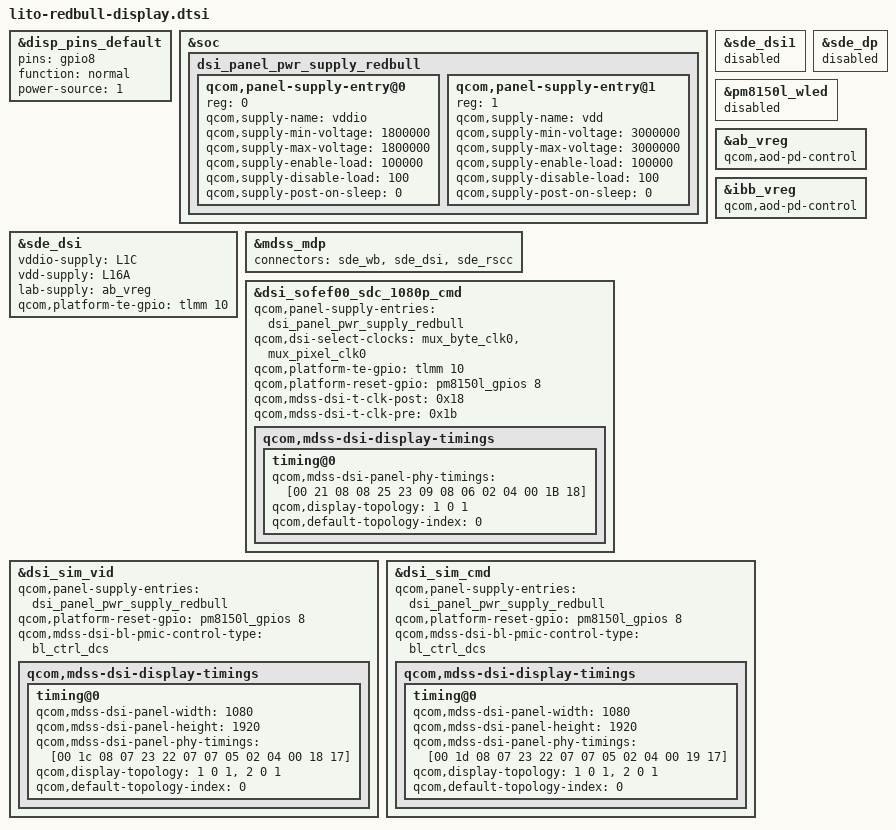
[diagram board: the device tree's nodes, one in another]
// SPDX-License-Identifier: GPL-2.0
/* Copyright (c) 2019, The Linux Foundation. All rights reserved.
 *
 * This program is free software; you can redistribute it and/or modify
 * it under the terms of the GNU General Public License version 2 and
 * only version 2 as published by the Free Software Foundation.
 *
 * This program is distributed in the hope that it will be useful,
 * but WITHOUT ANY WARRANTY; without even the implied warranty of
 * MERCHANTABILITY or FITNESS FOR A PARTICULAR PURPOSE.  See the
 * GNU General Public License for more details.
 */

#include "qcom-base/lito-sde-display.dtsi"
#include "dsi-panel-sofef00-1080p-cmd.dtsi"

&disp_pins_default {
	pins = "gpio8";
	function = "normal";
	power-source = <1>;
};

&soc {
	dsi_panel_pwr_supply_redbull: dsi_panel_pwr_supply_redbull {
		#address-cells = <1>;
		#size-cells = <0>;

		qcom,panel-supply-entry@0 {
			reg = <0>;
			qcom,supply-name = "vddio";
			qcom,supply-min-voltage = <1800000>;
			qcom,supply-max-voltage = <1800000>;
			qcom,supply-enable-load = <100000>;
			qcom,supply-disable-load = <100>;
			qcom,supply-post-on-sleep = <0>;
		};

		qcom,panel-supply-entry@1 {
			reg = <1>;
			qcom,supply-name = "vdd";
			qcom,supply-min-voltage = <3000000>;
			qcom,supply-max-voltage = <3000000>;
			qcom,supply-enable-load = <100000>;
			qcom,supply-disable-load = <100>;
			qcom,supply-post-on-sleep = <0>;
		};
	};
};

&sde_dsi {
	vddio-supply = <&L1C>;
	vdd-supply = <&L16A>;
	lab-supply = <&ab_vreg>;
	qcom,platform-te-gpio = <&tlmm 10 0>;
};

&sde_dsi1 {
	status = "disabled";
};

&sde_dp {
	status = "disabled";
};

&mdss_mdp {
	connectors = <&sde_wb &sde_dsi &sde_rscc>;
};

&pm8150l_wled {
	status = "disabled";
};

&ab_vreg {
	qcom,aod-pd-control;
};

&ibb_vreg {
	qcom,aod-pd-control;
};

&dsi_sofef00_sdc_1080p_cmd {
	qcom,panel-supply-entries = <&dsi_panel_pwr_supply_redbull>;
	qcom,dsi-select-clocks = "mux_byte_clk0", "mux_pixel_clk0";
	qcom,platform-te-gpio = <&tlmm 10 0>;
	qcom,platform-reset-gpio = <&pm8150l_gpios 8 0>;
	qcom,mdss-dsi-t-clk-post = <0x18>;
	qcom,mdss-dsi-t-clk-pre = <0x1b>;
	qcom,mdss-dsi-display-timings {
		timing@0 {
			qcom,mdss-dsi-panel-phy-timings = [00 21 08 08 25 23 09
				08 06 02 04 00 1B 18];
			qcom,display-topology = <1 0 1>;
			qcom,default-topology-index = <0>;
		};
	};
};

&dsi_sim_vid {
	qcom,panel-supply-entries = <&dsi_panel_pwr_supply_redbull>;
	qcom,platform-reset-gpio = <&pm8150l_gpios 8 0>;
	qcom,mdss-dsi-bl-pmic-control-type = "bl_ctrl_dcs";
	qcom,mdss-dsi-display-timings {
		timing@0 {
			qcom,mdss-dsi-panel-width = <1080>;
			qcom,mdss-dsi-panel-height = <1920>;
			qcom,mdss-dsi-panel-phy-timings = [00 1c 08 07 23 22 07
				07 05 02 04 00 18 17];
			qcom,display-topology = <1 0 1>,
						<2 0 1>;
			qcom,default-topology-index = <0>;
		};
	};
};

&dsi_sim_cmd {
	qcom,panel-supply-entries = <&dsi_panel_pwr_supply_redbull>;
	qcom,platform-reset-gpio = <&pm8150l_gpios 8 0>;
	qcom,mdss-dsi-bl-pmic-control-type = "bl_ctrl_dcs";
	qcom,mdss-dsi-display-timings {
		timing@0 {
			qcom,mdss-dsi-panel-width = <1080>;
			qcom,mdss-dsi-panel-height = <1920>;
			qcom,mdss-dsi-panel-phy-timings = [00 1d 08 07 23 22 07
				07 05 02 04 00 19 17];
			qcom,display-topology = <1 0 1>,
						<2 0 1>;
			qcom,default-topology-index = <0>;
		};
	};
};
